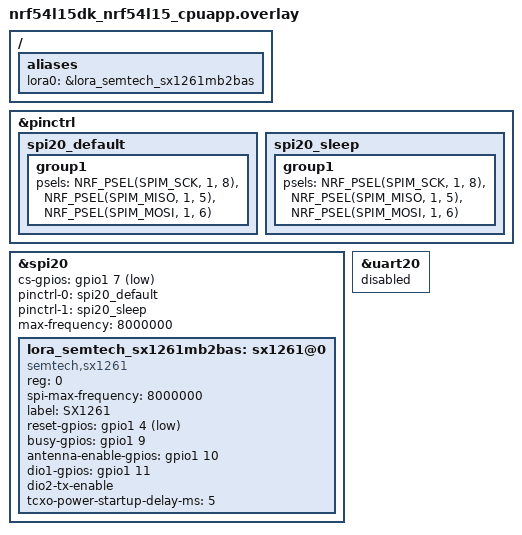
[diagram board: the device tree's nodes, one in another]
/ {
    aliases {
        lora0 = &lora_semtech_sx1261mb2bas; // or the actual connected pin
    };
};

&pinctrl {
    spi20_default: spi20_default {
     group1 {
      psels = <NRF_PSEL(SPIM_SCK, 1, 8)>,
              <NRF_PSEL(SPIM_MISO, 1, 5)>,
              <NRF_PSEL(SPIM_MOSI, 1, 6)>;
     };
    };   
    spi20_sleep: spi20_sleep {
        group1 {
         psels = <NRF_PSEL(SPIM_SCK, 1, 8)>,
                 <NRF_PSEL(SPIM_MISO, 1, 5)>,
                 <NRF_PSEL(SPIM_MOSI, 1, 6)>;
        };
       };   
};
&spi20 {
    status = "okay";
 
    cs-gpios = <&gpio1 7 GPIO_ACTIVE_LOW>;
    pinctrl-0 = <&spi20_default>;
    pinctrl-1 = <&spi20_sleep>;
    pinctrl-names = "default", "sleep";
    max-frequency = < 8000000 >;
    lora_semtech_sx1261mb2bas: sx1261@0 {
        compatible = "semtech,sx1261";
        reg = <0>;
        spi-max-frequency = <8000000>;
        label = "SX1261";
        reset-gpios = <&gpio1 4 GPIO_ACTIVE_LOW>;
        busy-gpios = <&gpio1 9 GPIO_ACTIVE_HIGH>; // done
        antenna-enable-gpios = <&gpio1 10 GPIO_ACTIVE_HIGH>;
        dio1-gpios = <&gpio1 11 GPIO_ACTIVE_HIGH>; // done
        dio2-tx-enable;
        tcxo-power-startup-delay-ms = <5>;
    };
};
&uart20 {
    status = "disabled";
};

// &uart30 {
//     status = "disabled";
// };
